VERSION ""

NS_ :

BS_:

BU_: XXX

BO_ 310 NEW_MSG_2: 8 XXX
 SG_ NEW_SIGNAL_1 : 50|1@0+ (1,0) [0|63] "" XXX

BO_ 208 NEW_MSG_1: 8 XXX
 SG_ NEW_SIGNAL_3 : 44|39@0+ (1,0) [0|1] "" XXX
 SG_ NEW_SIGNAL_6 : 15|8@0+ (1,0) [0|1] "" XXX
 SG_ NEW_SIGNAL_7 : 23|8@0+ (1,0) [0|1] "" XXX
 SG_ NEW_SIGNAL_1 : 7|64@0+ (1,0) [0|1] "" XXX
 SG_ NEW_SIGNAL_8 : 8|1@0+ (1,0) [0|7] "" XXX

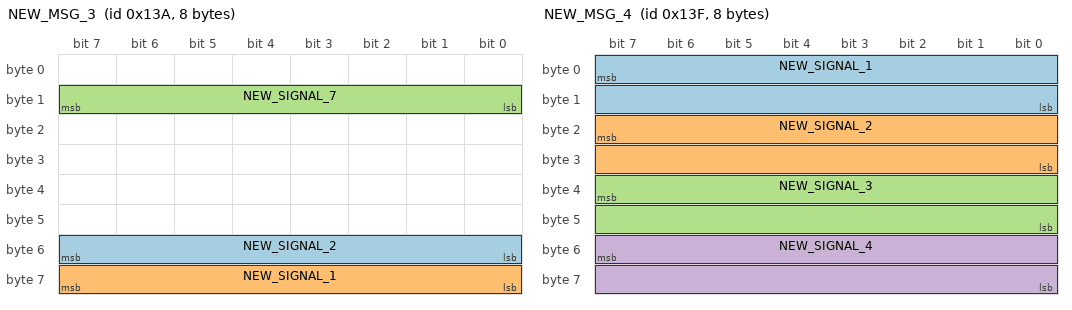
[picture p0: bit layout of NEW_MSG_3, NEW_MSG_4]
BO_ 314 NEW_MSG_3: 8 XXX
 SG_ NEW_SIGNAL_2 : 48|8@1+ (1,0) [0|255] "" XXX
 SG_ NEW_SIGNAL_1 : 56|8@1+ (1,0) [0|255] "" XXX
 SG_ NEW_SIGNAL_7 : 8|8@1+ (1,0) [0|255] "" XXX

BO_ 319 NEW_MSG_4: 8 XXX
 SG_ NEW_SIGNAL_1 : 7|16@0+ (1,0) [0|65535] "" XXX
 SG_ NEW_SIGNAL_2 : 23|16@0+ (1,0) [0|65535] "" XXX
 SG_ NEW_SIGNAL_3 : 39|16@0+ (1,0) [0|65535] "" XXX
 SG_ NEW_SIGNAL_4 : 55|16@0+ (1,0) [0|65535] "" XXX

BO_ 356 NEW_MSG_5: 8 XXX

BO_ 344 NEW_MSG_6: 8 XXX
 SG_ NEW_SIGNAL_1 : 7|32@0+ (1,0) [0|4294967295] "" XXX
 SG_ NEW_SIGNAL_2 : 39|32@0+ (1,0) [0|4294967295] "" XXX

BO_ 380 NEW_MSG_7: 8 XXX
 SG_ NEW_SIGNAL_1 : 7|64@0+ (1,0) [0|18446744073709552000] "" XXX

BO_ 398 NEW_MSG_8: 8 XXX

BO_ 420 NEW_MSG_9: 8 XXX

BO_ 432 NEW_MSG_10: 8 XXX
